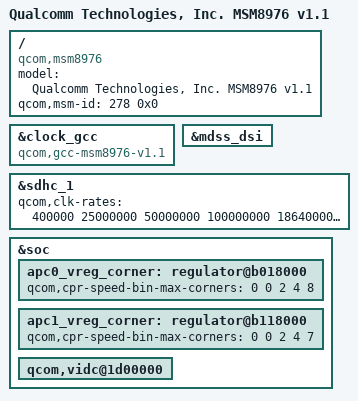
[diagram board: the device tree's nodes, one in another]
// SPDX-License-Identifier: GPL-2.0
// Copyright (c) 2015, The Linux Foundation. All rights reserved.
// Copyright (c) 2024, Benarji Anand <benarji385@gmail.com>

/*
 * NOTE:
 * As a general rule, only version-specific property overrides should be placed
 * inside this file. However, device definitions should be placed inside the
 * msm8976.dtsi file.
 */

#include "msm8976.dtsi"

/ {
	model = "Qualcomm Technologies, Inc. MSM8976 v1.1";
	compatible = "qcom,msm8976";
	qcom,msm-id = <278 0x0>;
};

/* Overwrite with V1.1 spec */
&clock_gcc {
	compatible = "qcom,gcc-msm8976-v1.1";
};

&mdss_dsi {
	/delete-property/ qcom,split-dsi-independent-pll;
};

&sdhc_1 {
	qcom,clk-rates = <400000 25000000 50000000 100000000
					186400000 372800000>;
};

&soc {
	apc0_vreg_corner: regulator@b018000 {
		/delete-property/ qcom,cpr-fuse-version-map;
		/delete-property/ qcom,cpr-quotient-adjustment;

		qcom,cpr-speed-bin-max-corners =
				<0 0 2 4 8>;
	};

	apc1_vreg_corner: regulator@b118000 {
		/delete-property/ qcom,cpr-fuse-version-map;
		/delete-property/ qcom,cpr-quotient-adjustment;

		qcom,cpr-speed-bin-max-corners =
				<0 0 2 4 7>;
	};

	qcom,vidc@1d00000 {
		/delete-property/ qcom,reset-clock-control;
		/delete-property/ qcom,regulator-scaling;
	};
};
